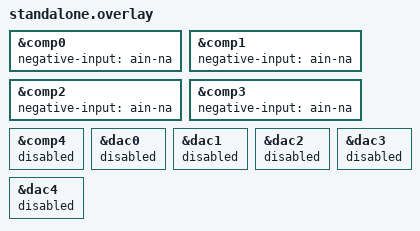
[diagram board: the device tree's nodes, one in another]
/*
 * SPDX-FileCopyrightText: Copyright (c) 2026 Infineon Technologies AG,
 * SPDX-FileCopyrightText: or an affiliate of Infineon Technologies AG.
 *
 * SPDX-License-Identifier: Apache-2.0
 *
 * Build coverage for the HPPASS CSG comparator in standalone (DAC-less)
 * mode.  Slices 0-3 select an external analog input (AIN_NA) as the
 * negative input, so the comparator driver builds without the paired
 * in-slice DAC or CONFIG_DAC.  The CSG MFD parent is enabled by the board
 * dtsi; this overlay only retargets the comparator inputs and disables the
 * unused DAC slices. Slice 4 has no external negative input and is disabled.
 */

&comp0 {
	negative-input = "ain-na";
};

&comp1 {
	negative-input = "ain-na";
};

&comp2 {
	negative-input = "ain-na";
};

&comp3 {
	negative-input = "ain-na";
};

&comp4 {
	status = "disabled";
};

&dac0 {
	status = "disabled";
};

&dac1 {
	status = "disabled";
};

&dac2 {
	status = "disabled";
};

&dac3 {
	status = "disabled";
};

&dac4 {
	status = "disabled";
};
